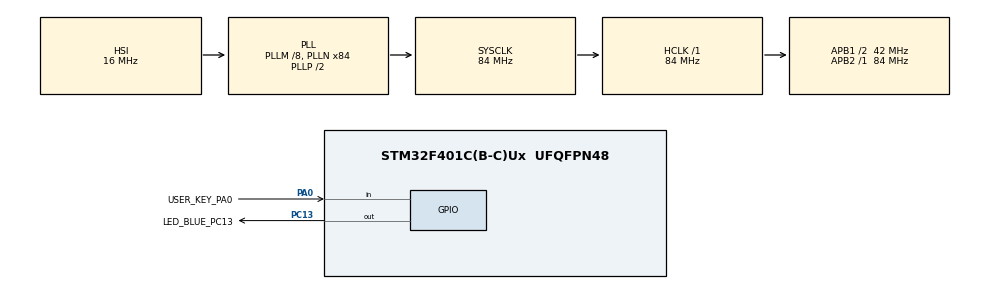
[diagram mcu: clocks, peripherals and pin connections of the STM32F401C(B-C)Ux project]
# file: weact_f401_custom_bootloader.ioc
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Mcu.Family=STM32F4
Mcu.Name=STM32F401C(B-C)Ux
Mcu.Package=UFQFPN48
NVIC.PriorityGroup=NVIC_PRIORITYGROUP_4
PA0-WKUP.GPIO_Label=USER_KEY_PA0
PA0-WKUP.Signal=GPIO_Input
PA13.Mode=Serial_Wire
PA13.Signal=SYS_JTMS-SWDIO
PA14.Mode=Serial_Wire
PA14.Signal=SYS_JTCK-SWCLK
PC13-ANTI_TAMP.GPIO_Label=LED_BLUE_PC13
PC13-ANTI_TAMP.Signal=GPIO_Output
PC14-OSC32_IN.Mode=LSE-External-Oscillator
PC14-OSC32_IN.Signal=RCC_OSC32_IN
PC15-OSC32_OUT.Mode=LSE-External-Oscillator
PC15-OSC32_OUT.Signal=RCC_OSC32_OUT
PH0\ -\ OSC_IN.Mode=HSE-External-Oscillator
PH0\ -\ OSC_IN.Signal=RCC_OSC_IN
PH1\ -\ OSC_OUT.Mode=HSE-External-Oscillator
PH1\ -\ OSC_OUT.Signal=RCC_OSC_OUT
ProjectManager.HeapSize=0x200
ProjectManager.StackSize=0x400
ProjectManager.TargetToolchain=STM32CubeIDE
RCC.48MHZClocksFreq_Value=42000000
RCC.AHBFreq_Value=84000000
RCC.APB1CLKDivider=RCC_HCLK_DIV2
RCC.APB1Freq_Value=42000000
RCC.APB1TimFreq_Value=84000000
RCC.APB2Freq_Value=84000000
RCC.APB2TimFreq_Value=84000000
RCC.CortexFreq_Value=84000000
RCC.HCLKFreq_Value=84000000
RCC.HSE_VALUE=25000000
RCC.HSI_VALUE=16000000
RCC.PLLM=8
RCC.PLLN=84
RCC.SYSCLKFreq_VALUE=84000000
RCC.SYSCLKSource=RCC_SYSCLKSOURCE_PLLCLK
RCC.VCOOutputFreq_Value=168000000
board=custom

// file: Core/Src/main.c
/* USER CODE BEGIN Header */
/**
  ******************************************************************************
  * @file           : main.c
  * @brief          : Main program body
  ******************************************************************************
  * @attention
  *
  * Copyright (c) 2026 STMicroelectronics.
  * All rights reserved.
  *
  * This software is licensed under terms that can be found in the LICENSE file
  * in the root directory of this software component.
  * If no LICENSE file comes with this software, it is provided AS-IS.
  *
  ******************************************************************************
  */
/* USER CODE END Header */
#include "main.h"
#include "gpio.h"

/* USER CODE BEGIN Includes */
#include "stdio.h"
/* USER CODE END Includes */

void SystemClock_Config(void);
/* USER CODE BEGIN PFP */

void jump_to_app(uint32_t app_addr);

int _write(int file, char *ptr, int len) {
    for (int i = 0; i < len; i++) {
        ITM_SendChar((*ptr++));
    }
    return len;
}

/* USER CODE END PFP */
static uint8_t status_pin;

/* USER CODE BEGIN 0 */

#define APP_ADDRESS_BLINK 0x08008000
#define APP_ADDRESS_BUTTON 0x08020000

/* USER CODE END 0 */

int main(void)
{

  /* USER CODE BEGIN 1 */
	printf("Into Custom Boot Loader");
  /* USER CODE END 1 */

  /* MCU Configuration--------------------------------------------------------*/

  /* Reset of all peripherals, Initializes the Flash interface and the Systick. */
  HAL_Init();

  /* Configure the system clock */
  SystemClock_Config();

  /* Initialize all configured peripherals */
  MX_GPIO_Init();
  /* USER CODE BEGIN 2 */

  status_pin = HAL_GPIO_ReadPin(USER_KEY_PA0_GPIO_Port, USER_KEY_PA0_Pin);

  if ( status_pin )
  {
	  jump_to_app(APP_ADDRESS_BLINK);
  }
  else
  {
	  jump_to_app(APP_ADDRESS_BUTTON);
  }

  /* USER CODE END 2 */

  /* Infinite loop */
  while (1)
  {

  }
}

void SystemClock_Config(void)
{
  RCC_OscInitTypeDef RCC_OscInitStruct = {0};
  RCC_ClkInitTypeDef RCC_ClkInitStruct = {0};

  /** Configure the main internal regulator output voltage
  */
  __HAL_RCC_PWR_CLK_ENABLE();
  __HAL_PWR_VOLTAGESCALING_CONFIG(PWR_REGULATOR_VOLTAGE_SCALE2);

  /** Initializes the RCC Oscillators according to the specified parameters
  * in the RCC_OscInitTypeDef structure.
  */
  RCC_OscInitStruct.OscillatorType = RCC_OSCILLATORTYPE_HSI;
  RCC_OscInitStruct.HSIState = RCC_HSI_ON;
  RCC_OscInitStruct.HSICalibrationValue = RCC_HSICALIBRATION_DEFAULT;
  RCC_OscInitStruct.PLL.PLLState = RCC_PLL_ON;
  RCC_OscInitStruct.PLL.PLLSource = RCC_PLLSOURCE_HSI;
  RCC_OscInitStruct.PLL.PLLM = 8;
  RCC_OscInitStruct.PLL.PLLN = 84;
  RCC_OscInitStruct.PLL.PLLP = RCC_PLLP_DIV2;
  RCC_OscInitStruct.PLL.PLLQ = 4;
  if (HAL_RCC_OscConfig(&RCC_OscInitStruct) != HAL_OK)
  {
    Error_Handler();
  }

  /** Initializes the CPU, AHB and APB buses clocks
  */
  RCC_ClkInitStruct.ClockType = RCC_CLOCKTYPE_HCLK|RCC_CLOCKTYPE_SYSCLK
                              |RCC_CLOCKTYPE_PCLK1|RCC_CLOCKTYPE_PCLK2;
  RCC_ClkInitStruct.SYSCLKSource = RCC_SYSCLKSOURCE_PLLCLK;
  RCC_ClkInitStruct.AHBCLKDivider = RCC_SYSCLK_DIV1;
  RCC_ClkInitStruct.APB1CLKDivider = RCC_HCLK_DIV2;
  RCC_ClkInitStruct.APB2CLKDivider = RCC_HCLK_DIV1;

  if (HAL_RCC_ClockConfig(&RCC_ClkInitStruct, FLASH_LATENCY_2) != HAL_OK)
  {
    Error_Handler();
  }
}

/* USER CODE BEGIN 4 */

typedef void (*pFunction)(void);

/**
 * @brief  Jump execution from bootloader to application firmware.
 *
 * This function transfers CPU control to an application located at the
 * specified flash address. It performs a full context cleanup before
 * switching execution, including:
 *
 * - Disabling global interrupts
 * - Deinitializing HAL and RCC configuration
 * - Disabling SysTick timer
 * - Clearing and disabling all NVIC interrupts
 * - Validating application stack pointer
 * - Relocating vector table (VTOR)
 * - Setting Main Stack Pointer (MSP)
 * - Jumping to application reset handler
 *
 * @param[in] app_addr  Start address of the application firmware.
 *                      This address must point to the application's
 *                      vector table in Flash.
 *
 * @note
 * The first word at @p app_addr must contain a valid initial stack
 * pointer (SRAM address). The second word must contain the reset
 * handler entry point.
 *
 * @warning
 * - The application must be built with correct FLASH origin.
 * - VECT_TAB_OFFSET must match the application base address.
 * - This function does not return.
 *
 * @retval None
 */
void jump_to_app(uint32_t app_addr)
{
    uint32_t stack;
    pFunction app_reset_handler;

    /* Disable global interrupts */
    __disable_irq();

    /* Deinitialize HAL and reset clock configuration */
    HAL_DeInit();
    HAL_RCC_DeInit();

    /* Disable SysTick timer */
    SysTick->CTRL = 0;
    SysTick->LOAD = 0;
    SysTick->VAL  = 0;

    /* Disable and clear all NVIC interrupts */
    for (uint32_t i = 0; i < 5; i++)
    {
        NVIC->ICER[i] = 0xFFFFFFFF;
        NVIC->ICPR[i] = 0xFFFFFFFF;
    }

    /* Validate initial stack pointer (must point to SRAM) */
    stack = *(volatile uint32_t*)app_addr;
    if ((stack & 0x2FFE0000) != 0x20000000)
        return;

    /* Relocate vector table to application base address */
    SCB->VTOR = app_addr;

    /* Set Main Stack Pointer to application's stack pointer */
    __set_MSP(stack);

    /* Read application's reset handler address */
    app_reset_handler =
        (pFunction)*(volatile uint32_t*)(app_addr + 4);

    /* Jump to application reset handler */
    app_reset_handler();

    /* Should never reach here */
    while (1);
}
/* USER CODE END 4 */

void Error_Handler(void)
{
  __disable_irq();
  while (1)
  {
  }
}
